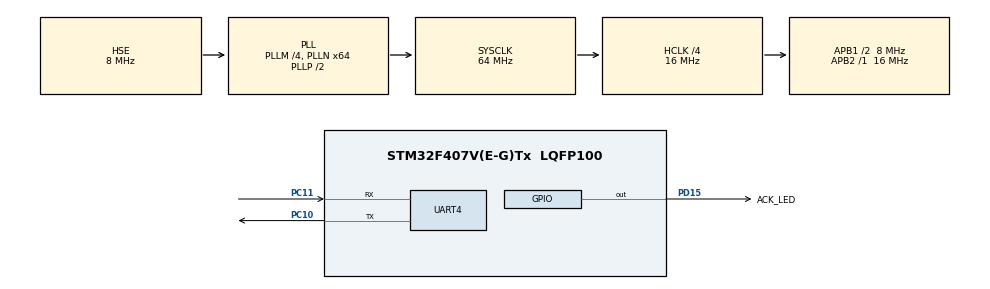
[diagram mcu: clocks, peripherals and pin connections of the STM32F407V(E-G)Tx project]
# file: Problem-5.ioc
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ADC1.Channel-0\#ChannelRegularConversion=ADC_CHANNEL_TEMPSENSOR
ADC1.EOCSelection=ADC_EOC_SEQ_CONV
ADC1.ExternalTrigConv=ADC_EXTERNALTRIGCONV_T8_TRGO
ADC1.ExternalTrigConvEdge=ADC_EXTERNALTRIGCONVEDGE_RISING
ADC1.NbrOfConversionFlag=1
ADC1.Rank-0\#ChannelRegularConversion=1
ADC1.SamplingTime-0\#ChannelRegularConversion=ADC_SAMPLETIME_3CYCLES
ADC1.master=1
Mcu.Family=STM32F4
Mcu.Name=STM32F407V(E-G)Tx
Mcu.Package=LQFP100
NVIC.ADC_IRQn=true\:0\:0\:false\:false\:true\:true\:true\:true
NVIC.PriorityGroup=NVIC_PRIORITYGROUP_0
NVIC.TIM8_UP_TIM13_IRQn=true\:0\:0\:false\:false\:true\:true\:true\:true
NVIC.UART4_IRQn=true\:0\:0\:false\:false\:true\:true\:true\:true
PC10.GPIO_PuPd=GPIO_NOPULL
PC10.Mode=Asynchronous
PC10.Signal=UART4_TX
PC11.GPIO_PuPd=GPIO_PULLUP
PC11.Mode=Asynchronous
PC11.Signal=UART4_RX
PD15.GPIO_Label=ACK_LED
PD15.Signal=GPIO_Output
PH0-OSC_IN.Mode=HSE-External-Oscillator
PH0-OSC_IN.Signal=RCC_OSC_IN
PH1-OSC_OUT.Mode=HSE-External-Oscillator
PH1-OSC_OUT.Signal=RCC_OSC_OUT
ProjectManager.HeapSize=0x200
ProjectManager.StackSize=0x400
ProjectManager.TargetToolchain=STM32CubeIDE
RCC.48MHZClocksFreq_Value=18285714.285714287
RCC.AHBCLKDivider=RCC_SYSCLK_DIV4
RCC.AHBFreq_Value=16000000
RCC.APB1CLKDivider=RCC_HCLK_DIV2
RCC.APB1Freq_Value=8000000
RCC.APB1TimFreq_Value=16000000
RCC.APB2Freq_Value=16000000
RCC.APB2TimFreq_Value=16000000
RCC.CortexFreq_Value=16000000
RCC.HCLKFreq_Value=16000000
RCC.HSE_VALUE=8000000
RCC.HSI_VALUE=16000000
RCC.PLLM=4
RCC.PLLN=64
RCC.PLLQ=7
RCC.PLLSourceVirtual=RCC_PLLSOURCE_HSE
RCC.SYSCLKFreq_VALUE=64000000
RCC.SYSCLKSource=RCC_SYSCLKSOURCE_PLLCLK
RCC.VCOOutputFreq_Value=128000000
TIM8.Period=1500-1
TIM8.Prescaler=56000-1
TIM8.TIM_MasterOutputTrigger=TIM_TRGO_UPDATE
UART4.VirtualMode=Asynchronous
VP_ADC1_TempSens_Input.Mode=IN-TempSens
VP_TIM8_VS_ClockSourceINT.Mode=Internal
board=STM32F407G-DISC1

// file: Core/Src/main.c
/* USER CODE BEGIN Header */
/**
  ******************************************************************************
  * @file           : main.c
  * @brief          : Main program body
  ******************************************************************************
  * @attention
  *
  * Copyright (c) 2024 STMicroelectronics.
  * All rights reserved.
  *
  * This software is licensed under terms that can be found in the LICENSE file
  * in the root directory of this software component.
  * If no LICENSE file comes with this software, it is provided AS-IS.
  *
  ******************************************************************************
  */
/* USER CODE END Header */
#include "main.h"

/* USER CODE BEGIN Includes */
#include <stdio.h>
#include <string.h>
/* USER CODE END Includes */

/* USER CODE BEGIN PD */
#define MSG_BUFFER_SIZE			19U
#define V25						0.76
#define AVG_SLOPE				2.5
#define TEMP_CONST				25U
#define RESOLUTION 				4095U
#define VDD 					3.3
//#define MASTER_BOARD
/* USER CODE END PD */

ADC_HandleTypeDef hadc1;

TIM_HandleTypeDef htim8;

UART_HandleTypeDef huart4;

/* USER CODE BEGIN PV */
uint8_t AdcFlag = 0  ;
uint8_t RxFlag = 0;
uint8_t ByteBuffer[1];
uint16_t BufferIndex = 0;
float Vsense = 0;
float AdcValue = 0;
float TempValue = 0;
char JsonMsgString[] = "{temperature:%.2f}";
char MessageBuffer[MSG_BUFFER_SIZE];
/* USER CODE END PV */

void SystemClock_Config(void);
static void MX_GPIO_Init(void);
static void MX_ADC1_Init(void);
static void MX_UART4_Init(void);
static void MX_TIM8_Init(void);

int main(void)
{

  /* MCU Configuration--------------------------------------------------------*/

  /* Reset of all peripherals, Initializes the Flash interface and the Systick. */
  HAL_Init();

  /* Configure the system clock */
  SystemClock_Config();

  /* Initialize all configured peripherals */
  MX_GPIO_Init();
  MX_ADC1_Init();
  MX_UART4_Init();
  MX_TIM8_Init();
  /* USER CODE BEGIN 2 */
#ifdef MASTER_BOARD

 if ( HAL_ADC_Start_IT(&hadc1)!= HAL_OK){
	 Error_Handler();
 }
 if (HAL_TIM_Base_Start_IT(&htim8)!= HAL_OK){
	 Error_Handler();
 }

#else
 if (HAL_UART_Receive_IT(&huart4, ByteBuffer, sizeof(ByteBuffer)) != HAL_OK ){
	 Error_Handler();
 }
#endif
  /* USER CODE END 2 */

  /* Infinite loop */
  while (1)
  {

    /* USER CODE BEGIN 3 */
#ifdef MASTER_BOARD
	  if(1 == AdcFlag)
	  {
        AdcValue = HAL_ADC_GetValue(&hadc1);
	    Vsense = (TempValue * VDD)/RESOLUTION;
	    TempValue = ((Vsense - V25)/AVG_SLOPE) + TEMP_CONST;
	    sprintf(MessageBuffer, JsonMsgString, TempValue);
	    if(HAL_UART_Transmit_IT(&huart4, (uint8_t *)MessageBuffer, MSG_BUFFER_SIZE) !=  HAL_OK )
	    {
	   	   Error_Handler();
	    }
	  AdcFlag = 0;

	  }
#else
	  if(1 == RxFlag)
	  {
           HAL_GPIO_WritePin(ACK_LED_GPIO_Port, ACK_LED_Pin, SET);
	       HAL_Delay(1000);
	       HAL_GPIO_WritePin(ACK_LED_GPIO_Port, ACK_LED_Pin, RESET);
	       RxFlag = 0;
	  }
#endif
  }
  /* USER CODE END 3 */
}

void SystemClock_Config(void)
{
  RCC_OscInitTypeDef RCC_OscInitStruct = {0};
  RCC_ClkInitTypeDef RCC_ClkInitStruct = {0};

  /** Configure the main internal regulator output voltage
  */
  __HAL_RCC_PWR_CLK_ENABLE();
  __HAL_PWR_VOLTAGESCALING_CONFIG(PWR_REGULATOR_VOLTAGE_SCALE1);

  /** Initializes the RCC Oscillators according to the specified parameters
  * in the RCC_OscInitTypeDef structure.
  */
  RCC_OscInitStruct.OscillatorType = RCC_OSCILLATORTYPE_HSE;
  RCC_OscInitStruct.HSEState = RCC_HSE_ON;
  RCC_OscInitStruct.PLL.PLLState = RCC_PLL_ON;
  RCC_OscInitStruct.PLL.PLLSource = RCC_PLLSOURCE_HSE;
  RCC_OscInitStruct.PLL.PLLM = 4;
  RCC_OscInitStruct.PLL.PLLN = 64;
  RCC_OscInitStruct.PLL.PLLP = RCC_PLLP_DIV2;
  RCC_OscInitStruct.PLL.PLLQ = 7;
  if (HAL_RCC_OscConfig(&RCC_OscInitStruct) != HAL_OK)
  {
    Error_Handler();
  }

  /** Initializes the CPU, AHB and APB buses clocks
  */
  RCC_ClkInitStruct.ClockType = RCC_CLOCKTYPE_HCLK|RCC_CLOCKTYPE_SYSCLK
                              |RCC_CLOCKTYPE_PCLK1|RCC_CLOCKTYPE_PCLK2;
  RCC_ClkInitStruct.SYSCLKSource = RCC_SYSCLKSOURCE_PLLCLK;
  RCC_ClkInitStruct.AHBCLKDivider = RCC_SYSCLK_DIV4;
  RCC_ClkInitStruct.APB1CLKDivider = RCC_HCLK_DIV2;
  RCC_ClkInitStruct.APB2CLKDivider = RCC_HCLK_DIV1;

  if (HAL_RCC_ClockConfig(&RCC_ClkInitStruct, FLASH_LATENCY_0) != HAL_OK)
  {
    Error_Handler();
  }
}

static void MX_ADC1_Init(void)
{

  ADC_ChannelConfTypeDef sConfig = {0};

  /** Configure the global features of the ADC (Clock, Resolution, Data Alignment and number of conversion)
  */
  hadc1.Instance = ADC1;
  hadc1.Init.ClockPrescaler = ADC_CLOCK_SYNC_PCLK_DIV2;
  hadc1.Init.Resolution = ADC_RESOLUTION_12B;
  hadc1.Init.ScanConvMode = DISABLE;
  hadc1.Init.ContinuousConvMode = DISABLE;
  hadc1.Init.DiscontinuousConvMode = DISABLE;
  hadc1.Init.ExternalTrigConvEdge = ADC_EXTERNALTRIGCONVEDGE_RISING;
  hadc1.Init.ExternalTrigConv = ADC_EXTERNALTRIGCONV_T8_TRGO;
  hadc1.Init.DataAlign = ADC_DATAALIGN_RIGHT;
  hadc1.Init.NbrOfConversion = 1;
  hadc1.Init.DMAContinuousRequests = DISABLE;
  hadc1.Init.EOCSelection = ADC_EOC_SEQ_CONV;
  if (HAL_ADC_Init(&hadc1) != HAL_OK)
  {
    Error_Handler();
  }

  /** Configure for the selected ADC regular channel its corresponding rank in the sequencer and its sample time.
  */
  sConfig.Channel = ADC_CHANNEL_TEMPSENSOR;
  sConfig.Rank = 1;
  sConfig.SamplingTime = ADC_SAMPLETIME_3CYCLES;
  if (HAL_ADC_ConfigChannel(&hadc1, &sConfig) != HAL_OK)
  {
    Error_Handler();
  }

}

static void MX_TIM8_Init(void)
{

  TIM_ClockConfigTypeDef sClockSourceConfig = {0};
  TIM_MasterConfigTypeDef sMasterConfig = {0};

  htim8.Instance = TIM8;
  htim8.Init.Prescaler = 56000-1;
  htim8.Init.CounterMode = TIM_COUNTERMODE_UP;
  htim8.Init.Period = 1500-1;
  htim8.Init.ClockDivision = TIM_CLOCKDIVISION_DIV1;
  htim8.Init.RepetitionCounter = 0;
  htim8.Init.AutoReloadPreload = TIM_AUTORELOAD_PRELOAD_DISABLE;
  if (HAL_TIM_Base_Init(&htim8) != HAL_OK)
  {
    Error_Handler();
  }
  sClockSourceConfig.ClockSource = TIM_CLOCKSOURCE_INTERNAL;
  if (HAL_TIM_ConfigClockSource(&htim8, &sClockSourceConfig) != HAL_OK)
  {
    Error_Handler();
  }
  sMasterConfig.MasterOutputTrigger = TIM_TRGO_UPDATE;
  sMasterConfig.MasterSlaveMode = TIM_MASTERSLAVEMODE_DISABLE;
  if (HAL_TIMEx_MasterConfigSynchronization(&htim8, &sMasterConfig) != HAL_OK)
  {
    Error_Handler();
  }

}

static void MX_UART4_Init(void)
{

  huart4.Instance = UART4;
  huart4.Init.BaudRate = 115200;
  huart4.Init.WordLength = UART_WORDLENGTH_8B;
  huart4.Init.StopBits = UART_STOPBITS_1;
  huart4.Init.Parity = UART_PARITY_NONE;
  huart4.Init.Mode = UART_MODE_TX_RX;
  huart4.Init.HwFlowCtl = UART_HWCONTROL_NONE;
  huart4.Init.OverSampling = UART_OVERSAMPLING_16;
  if (HAL_UART_Init(&huart4) != HAL_OK)
  {
    Error_Handler();
  }

}

static void MX_GPIO_Init(void)
{
  GPIO_InitTypeDef GPIO_InitStruct = {0};

  /* GPIO Ports Clock Enable */
  __HAL_RCC_GPIOH_CLK_ENABLE();
  __HAL_RCC_GPIOD_CLK_ENABLE();
  __HAL_RCC_GPIOC_CLK_ENABLE();

  /*Configure GPIO pin Output Level */
  HAL_GPIO_WritePin(ACK_LED_GPIO_Port, ACK_LED_Pin, GPIO_PIN_RESET);

  /*Configure GPIO pin : ACK_LED_Pin */
  GPIO_InitStruct.Pin = ACK_LED_Pin;
  GPIO_InitStruct.Mode = GPIO_MODE_OUTPUT_PP;
  GPIO_InitStruct.Pull = GPIO_NOPULL;
  GPIO_InitStruct.Speed = GPIO_SPEED_FREQ_LOW;
  HAL_GPIO_Init(ACK_LED_GPIO_Port, &GPIO_InitStruct);

}

/* USER CODE BEGIN 4 */
void HAL_ADC_ConvCpltCallback(ADC_HandleTypeDef *hadc)
{
	if(hadc->Instance == ADC1)
	{
		AdcFlag = 1;
	}
}

void HAL_UART_RxCpltCallback(UART_HandleTypeDef *huart)
{
	if (huart->Instance == UART4)
		{

		MessageBuffer[BufferIndex] = ByteBuffer[0];
        if (BufferIndex >= sizeof(MessageBuffer))
	      {
		        BufferIndex = 0;
	      }

		++BufferIndex;
	    HAL_UART_Receive_IT(&huart4, ByteBuffer, sizeof(ByteBuffer));

	    if(BufferIndex == MSG_BUFFER_SIZE-1)
	      {
	    	RxFlag = 1;
	      }

		}
}

void HAL_UART_TxCpltCallback(UART_HandleTypeDef *huart)
{
	__NOP();
}

/* USER CODE END 4 */

void Error_Handler(void)
{
  __disable_irq();
  while (1)
  {
  }
}
